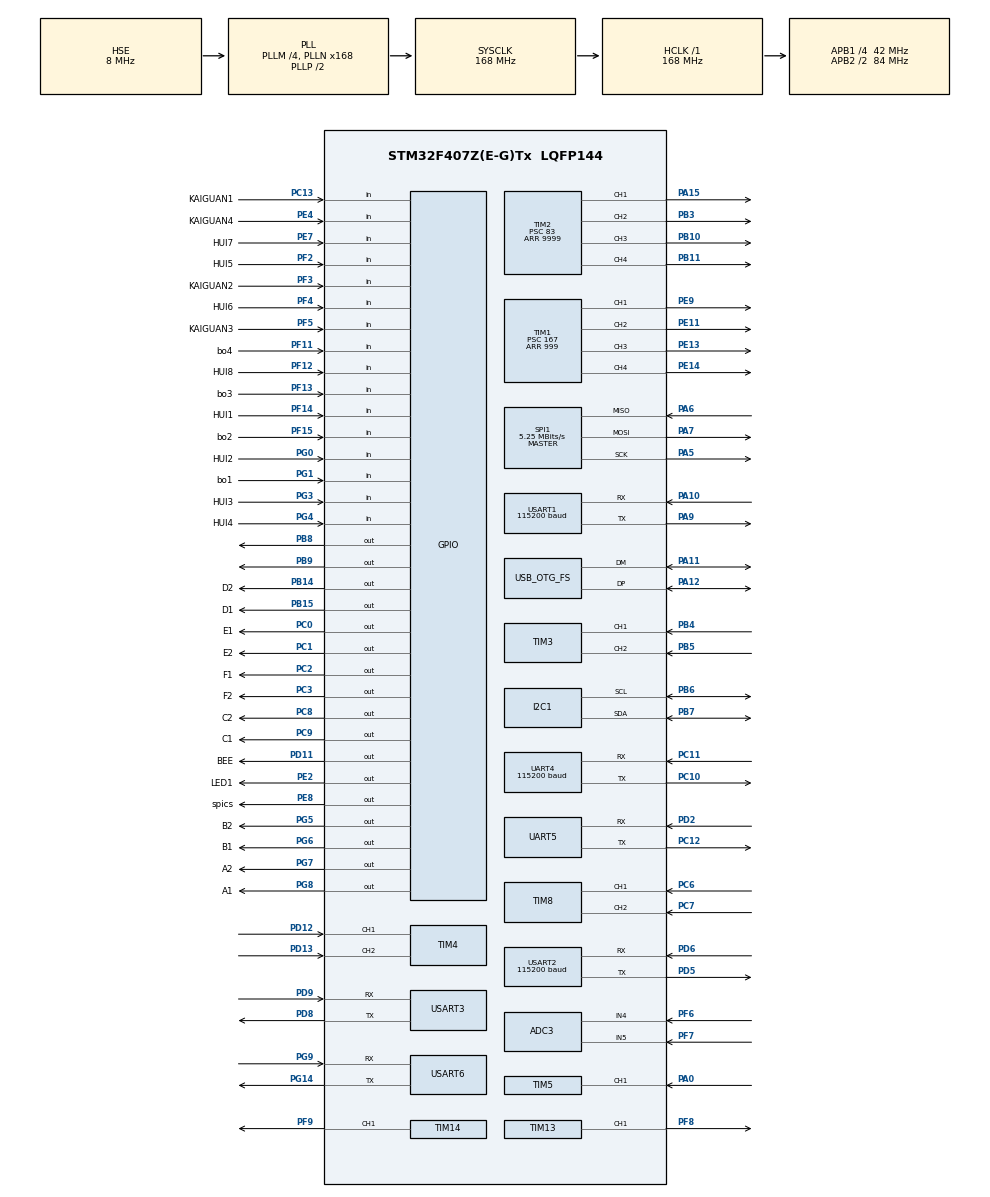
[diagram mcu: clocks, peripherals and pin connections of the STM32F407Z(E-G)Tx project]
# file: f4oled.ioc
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ADC3.Channel-0\#ChannelRegularConversion=ADC_CHANNEL_4
ADC3.Channel-1\#ChannelRegularConversion=ADC_CHANNEL_5
ADC3.ContinuousConvMode=ENABLE
ADC3.DMAContinuousRequests=ENABLE
ADC3.EOCSelection=ADC_EOC_SEQ_CONV
ADC3.NbrOfConversion=2
ADC3.NbrOfConversionFlag=1
ADC3.Rank-0\#ChannelRegularConversion=1
ADC3.Rank-1\#ChannelRegularConversion=2
ADC3.SamplingTime-0\#ChannelRegularConversion=ADC_SAMPLETIME_15CYCLES
ADC3.SamplingTime-1\#ChannelRegularConversion=ADC_SAMPLETIME_15CYCLES
ADC3.ScanConvMode=ENABLE
Dma.ADC3.8.Direction=DMA_PERIPH_TO_MEMORY
Dma.ADC3.8.FIFOMode=DMA_FIFOMODE_DISABLE
Dma.ADC3.8.Instance=DMA2_Stream0
Dma.ADC3.8.MemDataAlignment=DMA_MDATAALIGN_HALFWORD
Dma.ADC3.8.MemInc=DMA_MINC_ENABLE
Dma.ADC3.8.Mode=DMA_CIRCULAR
Dma.ADC3.8.PeriphDataAlignment=DMA_PDATAALIGN_HALFWORD
Dma.ADC3.8.PeriphInc=DMA_PINC_DISABLE
Dma.ADC3.8.Priority=DMA_PRIORITY_LOW
Dma.Request0=USART1_RX
Dma.Request1=USART1_TX
Dma.Request10=USART3_TX
Dma.Request2=UART5_RX
Dma.Request3=UART5_TX
Dma.Request4=UART4_RX
Dma.Request5=UART4_TX
Dma.Request6=USART2_RX
Dma.Request7=USART2_TX
Dma.Request8=ADC3
Dma.Request9=USART3_RX
Dma.UART4_RX.4.Direction=DMA_PERIPH_TO_MEMORY
Dma.UART4_RX.4.FIFOMode=DMA_FIFOMODE_DISABLE
Dma.UART4_RX.4.Instance=DMA1_Stream2
Dma.UART4_RX.4.MemDataAlignment=DMA_MDATAALIGN_BYTE
Dma.UART4_RX.4.MemInc=DMA_MINC_ENABLE
Dma.UART4_RX.4.Mode=DMA_NORMAL
Dma.UART4_RX.4.PeriphDataAlignment=DMA_PDATAALIGN_BYTE
Dma.UART4_RX.4.PeriphInc=DMA_PINC_DISABLE
Dma.UART4_RX.4.Priority=DMA_PRIORITY_LOW
Dma.UART4_TX.5.Direction=DMA_MEMORY_TO_PERIPH
Dma.UART4_TX.5.FIFOMode=DMA_FIFOMODE_DISABLE
Dma.UART4_TX.5.Instance=DMA1_Stream4
Dma.UART4_TX.5.MemDataAlignment=DMA_MDATAALIGN_BYTE
Dma.UART4_TX.5.MemInc=DMA_MINC_ENABLE
Dma.UART4_TX.5.Mode=DMA_NORMAL
Dma.UART4_TX.5.PeriphDataAlignment=DMA_PDATAALIGN_BYTE
Dma.UART4_TX.5.PeriphInc=DMA_PINC_DISABLE
Dma.UART4_TX.5.Priority=DMA_PRIORITY_LOW
Dma.UART5_RX.2.Direction=DMA_PERIPH_TO_MEMORY
Dma.UART5_RX.2.FIFOMode=DMA_FIFOMODE_DISABLE
Dma.UART5_RX.2.Instance=DMA1_Stream0
Dma.UART5_RX.2.MemDataAlignment=DMA_MDATAALIGN_BYTE
Dma.UART5_RX.2.MemInc=DMA_MINC_ENABLE
Dma.UART5_RX.2.Mode=DMA_NORMAL
Dma.UART5_RX.2.PeriphDataAlignment=DMA_PDATAALIGN_BYTE
Dma.UART5_RX.2.PeriphInc=DMA_PINC_DISABLE
Dma.UART5_RX.2.Priority=DMA_PRIORITY_LOW
Dma.UART5_TX.3.Direction=DMA_MEMORY_TO_PERIPH
Dma.UART5_TX.3.FIFOMode=DMA_FIFOMODE_DISABLE
Dma.UART5_TX.3.Instance=DMA1_Stream7
Dma.UART5_TX.3.MemDataAlignment=DMA_MDATAALIGN_BYTE
Dma.UART5_TX.3.MemInc=DMA_MINC_ENABLE
Dma.UART5_TX.3.Mode=DMA_NORMAL
Dma.UART5_TX.3.PeriphDataAlignment=DMA_PDATAALIGN_BYTE
Dma.UART5_TX.3.PeriphInc=DMA_PINC_DISABLE
Dma.UART5_TX.3.Priority=DMA_PRIORITY_LOW
Dma.USART1_RX.0.Direction=DMA_PERIPH_TO_MEMORY
Dma.USART1_RX.0.FIFOMode=DMA_FIFOMODE_DISABLE
Dma.USART1_RX.0.Instance=DMA2_Stream2
Dma.USART1_RX.0.MemDataAlignment=DMA_MDATAALIGN_BYTE
Dma.USART1_RX.0.MemInc=DMA_MINC_ENABLE
Dma.USART1_RX.0.Mode=DMA_NORMAL
Dma.USART1_RX.0.PeriphDataAlignment=DMA_PDATAALIGN_BYTE
Dma.USART1_RX.0.PeriphInc=DMA_PINC_DISABLE
Dma.USART1_RX.0.Priority=DMA_PRIORITY_LOW
Dma.USART1_TX.1.Direction=DMA_MEMORY_TO_PERIPH
Dma.USART1_TX.1.FIFOMode=DMA_FIFOMODE_DISABLE
Dma.USART1_TX.1.Instance=DMA2_Stream7
Dma.USART1_TX.1.MemDataAlignment=DMA_MDATAALIGN_BYTE
Dma.USART1_TX.1.MemInc=DMA_MINC_ENABLE
Dma.USART1_TX.1.Mode=DMA_NORMAL
Dma.USART1_TX.1.PeriphDataAlignment=DMA_PDATAALIGN_BYTE
Dma.USART1_TX.1.PeriphInc=DMA_PINC_DISABLE
Dma.USART1_TX.1.Priority=DMA_PRIORITY_LOW
Dma.USART2_RX.6.Direction=DMA_PERIPH_TO_MEMORY
Dma.USART2_RX.6.FIFOMode=DMA_FIFOMODE_DISABLE
Dma.USART2_RX.6.Instance=DMA1_Stream5
Dma.USART2_RX.6.MemDataAlignment=DMA_MDATAALIGN_BYTE
Dma.USART2_RX.6.MemInc=DMA_MINC_ENABLE
Dma.USART2_RX.6.Mode=DMA_NORMAL
Dma.USART2_RX.6.PeriphDataAlignment=DMA_PDATAALIGN_BYTE
Dma.USART2_RX.6.PeriphInc=DMA_PINC_DISABLE
Dma.USART2_RX.6.Priority=DMA_PRIORITY_LOW
Dma.USART2_TX.7.Direction=DMA_MEMORY_TO_PERIPH
Dma.USART2_TX.7.FIFOMode=DMA_FIFOMODE_DISABLE
Dma.USART2_TX.7.Instance=DMA1_Stream6
Dma.USART2_TX.7.MemDataAlignment=DMA_MDATAALIGN_BYTE
Dma.USART2_TX.7.MemInc=DMA_MINC_ENABLE
Dma.USART2_TX.7.Mode=DMA_NORMAL
Dma.USART2_TX.7.PeriphDataAlignment=DMA_PDATAALIGN_BYTE
Dma.USART2_TX.7.PeriphInc=DMA_PINC_DISABLE
Dma.USART2_TX.7.Priority=DMA_PRIORITY_LOW
Dma.USART3_RX.9.Direction=DMA_PERIPH_TO_MEMORY
Dma.USART3_RX.9.FIFOMode=DMA_FIFOMODE_DISABLE
Dma.USART3_RX.9.Instance=DMA1_Stream1
Dma.USART3_RX.9.MemDataAlignment=DMA_MDATAALIGN_BYTE
Dma.USART3_RX.9.MemInc=DMA_MINC_ENABLE
Dma.USART3_RX.9.Mode=DMA_NORMAL
Dma.USART3_RX.9.PeriphDataAlignment=DMA_PDATAALIGN_BYTE
Dma.USART3_RX.9.PeriphInc=DMA_PINC_DISABLE
Dma.USART3_RX.9.Priority=DMA_PRIORITY_LOW
Dma.USART3_TX.10.Direction=DMA_MEMORY_TO_PERIPH
Dma.USART3_TX.10.FIFOMode=DMA_FIFOMODE_DISABLE
Dma.USART3_TX.10.Instance=DMA1_Stream3
Dma.USART3_TX.10.MemDataAlignment=DMA_MDATAALIGN_BYTE
Dma.USART3_TX.10.MemInc=DMA_MINC_ENABLE
Dma.USART3_TX.10.Mode=DMA_NORMAL
Dma.USART3_TX.10.PeriphDataAlignment=DMA_PDATAALIGN_BYTE
Dma.USART3_TX.10.PeriphInc=DMA_PINC_DISABLE
Dma.USART3_TX.10.Priority=DMA_PRIORITY_LOW
Mcu.Family=STM32F4
Mcu.Name=STM32F407Z(E-G)Tx
Mcu.Package=LQFP144
NVIC.DMA1_Stream0_IRQn=true\:0\:0\:false\:false\:true\:false\:true\:true
NVIC.DMA1_Stream1_IRQn=true\:0\:0\:false\:false\:true\:false\:true\:true
NVIC.DMA1_Stream2_IRQn=true\:0\:0\:false\:false\:true\:false\:true\:true
NVIC.DMA1_Stream3_IRQn=true\:0\:0\:false\:false\:true\:false\:true\:true
NVIC.DMA1_Stream4_IRQn=true\:0\:0\:false\:false\:true\:false\:true\:true
NVIC.DMA1_Stream5_IRQn=true\:0\:0\:false\:false\:true\:false\:true\:true
NVIC.DMA1_Stream6_IRQn=true\:0\:0\:false\:false\:true\:false\:true\:true
NVIC.DMA1_Stream7_IRQn=true\:0\:0\:false\:false\:true\:false\:true\:true
NVIC.DMA2_Stream0_IRQn=true\:0\:0\:false\:false\:true\:false\:true\:true
NVIC.DMA2_Stream2_IRQn=true\:0\:0\:false\:false\:true\:false\:true\:true
NVIC.DMA2_Stream7_IRQn=true\:0\:0\:false\:false\:true\:false\:true\:true
NVIC.OTG_FS_IRQn=true\:5\:0\:false\:false\:true\:false\:true\:true
NVIC.PriorityGroup=NVIC_PRIORITYGROUP_4
NVIC.TIM1_BRK_TIM9_IRQn=true\:0\:0\:false\:false\:true\:true\:true\:true
NVIC.TIM2_IRQn=true\:0\:0\:false\:false\:true\:true\:true\:true
NVIC.TIM5_IRQn=true\:0\:0\:false\:false\:true\:true\:true\:true
NVIC.TIM8_UP_TIM13_IRQn=true\:0\:0\:false\:false\:true\:true\:true\:true
NVIC.UART4_IRQn=true\:0\:0\:false\:false\:true\:true\:true\:true
NVIC.UART5_IRQn=true\:0\:0\:false\:false\:true\:true\:true\:true
NVIC.USART1_IRQn=true\:0\:0\:false\:false\:true\:true\:true\:true
NVIC.USART2_IRQn=true\:0\:0\:false\:false\:true\:true\:true\:true
NVIC.USART3_IRQn=true\:0\:0\:false\:false\:true\:true\:true\:true
PA0-WKUP.Signal=S_TIM5_CH1
PA10.Mode=Asynchronous
PA10.Signal=USART1_RX
PA11.Mode=Device_Only
PA11.Signal=USB_OTG_FS_DM
PA12.Mode=Device_Only
PA12.Signal=USB_OTG_FS_DP
PA13.Mode=Serial_Wire
PA13.Signal=SYS_JTMS-SWDIO
PA14.Mode=Serial_Wire
PA14.Signal=SYS_JTCK-SWCLK
PA15.Signal=S_TIM2_CH1_ETR
PA5.Mode=Full_Duplex_Master
PA5.Signal=SPI1_SCK
PA6.Mode=Full_Duplex_Master
PA6.Signal=SPI1_MISO
PA7.Mode=Full_Duplex_Master
PA7.Signal=SPI1_MOSI
PA9.Mode=Asynchronous
PA9.Signal=USART1_TX
PB10.Signal=S_TIM2_CH3
PB11.Signal=S_TIM2_CH4
PB14.GPIO_Label=D2
PB14.Signal=GPIO_Output
PB15.GPIO_Label=D1
PB15.Signal=GPIO_Output
PB3.Signal=S_TIM2_CH2
PB4.Signal=S_TIM3_CH1
PB5.Signal=S_TIM3_CH2
PB6.Mode=I2C
PB6.Signal=I2C1_SCL
PB7.Mode=I2C
PB7.Signal=I2C1_SDA
PB8.GPIO_ModeDefaultOutputPP=GPIO_MODE_OUTPUT_OD
PB8.GPIO_PuPd=GPIO_NOPULL
PB8.Signal=GPIO_Output
PB9.GPIO_ModeDefaultOutputPP=GPIO_MODE_OUTPUT_OD
PB9.GPIO_PuPd=GPIO_NOPULL
PB9.Signal=GPIO_Output
PC0.GPIO_Label=E1
PC0.Signal=GPIO_Output
PC1.GPIO_Label=E2
PC1.Signal=GPIO_Output
PC10.Mode=Asynchronous
PC10.Signal=UART4_TX
PC11.Mode=Asynchronous
PC11.Signal=UART4_RX
PC12.Mode=Asynchronous
PC12.Signal=UART5_TX
PC13-ANTI_TAMP.GPIO_Label=KAIGUAN1
PC13-ANTI_TAMP.GPIO_PuPd=GPIO_PULLUP
PC13-ANTI_TAMP.Signal=GPIO_Input
PC2.GPIO_Label=F1
PC2.Signal=GPIO_Output
PC3.GPIO_Label=F2
PC3.Signal=GPIO_Output
PC6.Signal=S_TIM8_CH1
PC7.Signal=S_TIM8_CH2
PC8.GPIO_Label=C2
PC8.Signal=GPIO_Output
PC9.GPIO_Label=C1
PC9.Signal=GPIO_Output
PD11.GPIO_Label=BEE
PD11.Signal=GPIO_Output
PD12.Signal=S_TIM4_CH1
PD13.Signal=S_TIM4_CH2
PD2.Mode=Asynchronous
PD2.Signal=UART5_RX
PD5.Mode=Asynchronous
PD5.Signal=USART2_TX
PD6.Mode=Asynchronous
PD6.Signal=USART2_RX
PD8.Mode=Asynchronous
PD8.Signal=USART3_TX
PD9.Mode=Asynchronous
PD9.Signal=USART3_RX
PE11.Signal=S_TIM1_CH2
PE13.Signal=S_TIM1_CH3
PE14.Signal=S_TIM1_CH4
PE2.GPIO_Label=LED1
PE2.Signal=GPIO_Output
PE4.GPIO_Label=KAIGUAN4
PE4.GPIO_PuPd=GPIO_PULLUP
PE4.Signal=GPIO_Input
PE7.GPIO_Label=HUI7
PE7.Signal=GPIO_Input
PE8.GPIO_Label=spics
PE8.PinState=GPIO_PIN_SET
PE8.Signal=GPIO_Output
PE9.Signal=S_TIM1_CH1
PF11.GPIO_Label=bo4
PF11.GPIO_PuPd=GPIO_PULLDOWN
PF11.Signal=GPIO_Input
PF12.GPIO_Label=HUI8
PF12.Signal=GPIO_Input
PF13.GPIO_Label=bo3
PF13.GPIO_PuPd=GPIO_PULLDOWN
PF13.Signal=GPIO_Input
PF14.GPIO_Label=HUI1
PF14.Signal=GPIO_Input
PF15.GPIO_Label=bo2
PF15.GPIO_PuPd=GPIO_PULLDOWN
PF15.Signal=GPIO_Input
PF2.GPIO_Label=HUI5
PF2.Signal=GPIO_Input
PF3.GPIO_Label=KAIGUAN2
PF3.GPIO_PuPd=GPIO_PULLUP
PF3.Signal=GPIO_Input
PF4.GPIO_Label=HUI6
PF4.Signal=GPIO_Input
PF5.GPIO_Label=KAIGUAN3
PF5.GPIO_PuPd=GPIO_PULLUP
PF5.Signal=GPIO_Input
PF6.Mode=IN4
PF6.Signal=ADC3_IN4
PF7.Mode=IN5
PF7.Signal=ADC3_IN5
PF8.Signal=S_TIM13_CH1
PF9.Signal=S_TIM14_CH1
PG0.GPIO_Label=HUI2
PG0.Signal=GPIO_Input
PG1.GPIO_Label=bo1
PG1.GPIO_PuPd=GPIO_PULLDOWN
PG1.Signal=GPIO_Input
PG14.Mode=Asynchronous
PG14.Signal=USART6_TX
PG3.GPIO_Label=HUI3
PG3.Signal=GPIO_Input
PG4.GPIO_Label=HUI4
PG4.Signal=GPIO_Input
PG5.GPIO_Label=B2
PG5.Signal=GPIO_Output
PG6.GPIO_Label=B1
PG6.Signal=GPIO_Output
PG7.GPIO_Label=A2
PG7.Signal=GPIO_Output
PG8.GPIO_Label=A1
PG8.Signal=GPIO_Output
PG9.Mode=Asynchronous
PG9.Signal=USART6_RX
PH0-OSC_IN.Mode=HSE-External-Oscillator
PH0-OSC_IN.Signal=RCC_OSC_IN
PH1-OSC_OUT.Mode=HSE-External-Oscillator
PH1-OSC_OUT.Signal=RCC_OSC_OUT
ProjectManager.HeapSize=0x200
ProjectManager.StackSize=0x400
ProjectManager.TargetToolchain=CMake
RCC.48MHZClocksFreq_Value=48000000
RCC.AHBFreq_Value=168000000
RCC.APB1CLKDivider=RCC_HCLK_DIV4
RCC.APB1Freq_Value=42000000
RCC.APB1TimFreq_Value=84000000
RCC.APB2CLKDivider=RCC_HCLK_DIV2
RCC.APB2Freq_Value=84000000
RCC.APB2TimFreq_Value=168000000
RCC.CortexFreq_Value=168000000
RCC.HCLKFreq_Value=168000000
RCC.HSE_VALUE=8000000
RCC.HSI_VALUE=16000000
RCC.LSE_VALUE=32768
RCC.PLLM=4
RCC.PLLN=168
RCC.PLLQ=7
RCC.SYSCLKFreq_VALUE=168000000
RCC.SYSCLKSource=RCC_SYSCLKSOURCE_PLLCLK
RCC.VCOOutputFreq_Value=336000000
SH.S_TIM13_CH1.0=TIM13_CH1,PWM Generation1 CH1
SH.S_TIM14_CH1.0=TIM14_CH1,PWM Generation1 CH1
SH.S_TIM1_CH1.0=TIM1_CH1,PWM Generation1 CH1
SH.S_TIM1_CH2.0=TIM1_CH2,PWM Generation2 CH2
SH.S_TIM1_CH3.0=TIM1_CH3,PWM Generation3 CH3
SH.S_TIM1_CH4.0=TIM1_CH4,PWM Generation4 CH4
SH.S_TIM2_CH1_ETR.0=TIM2_CH1,PWM Generation1 CH1
SH.S_TIM2_CH2.0=TIM2_CH2,PWM Generation2 CH2
SH.S_TIM2_CH3.0=TIM2_CH3,PWM Generation3 CH3
SH.S_TIM2_CH4.0=TIM2_CH4,PWM Generation4 CH4
SH.S_TIM3_CH1.0=TIM3_CH1,Encoder_Interface
SH.S_TIM3_CH2.0=TIM3_CH2,Encoder_Interface
SH.S_TIM4_CH1.0=TIM4_CH1,Encoder_Interface
SH.S_TIM4_CH2.0=TIM4_CH2,Encoder_Interface
SH.S_TIM5_CH1.0=TIM5_CH1,Input_Capture1_from_TI1
SH.S_TIM8_CH1.0=TIM8_CH1,Encoder_Interface
SH.S_TIM8_CH2.0=TIM8_CH2,Encoder_Interface
SPI1.BaudRatePrescaler=SPI_BAUDRATEPRESCALER_16
SPI1.CalculateBaudRate=5.25 MBits/s
SPI1.Direction=SPI_DIRECTION_2LINES
SPI1.Mode=SPI_MODE_MASTER
SPI1.VirtualType=VM_MASTER
TIM1.Channel-PWM\ Generation1\ CH1=TIM_CHANNEL_1
TIM1.Channel-PWM\ Generation2\ CH2=TIM_CHANNEL_2
TIM1.Channel-PWM\ Generation3\ CH3=TIM_CHANNEL_3
TIM1.Channel-PWM\ Generation4\ CH4=TIM_CHANNEL_4
TIM1.Period=999
TIM1.Prescaler=167
TIM13.Channel=TIM_CHANNEL_1
TIM14.Channel=TIM_CHANNEL_1
TIM2.Channel-PWM\ Generation1\ CH1=TIM_CHANNEL_1
TIM2.Channel-PWM\ Generation2\ CH2=TIM_CHANNEL_2
TIM2.Channel-PWM\ Generation3\ CH3=TIM_CHANNEL_3
TIM2.Channel-PWM\ Generation4\ CH4=TIM_CHANNEL_4
TIM2.Period=9999
TIM2.Prescaler=83
TIM3.EncoderMode=TIM_ENCODERMODE_TI12
TIM3.IC2Polarity=TIM_ICPOLARITY_FALLING
TIM4.EncoderMode=TIM_ENCODERMODE_TI12
TIM4.IC2Polarity=TIM_ICPOLARITY_FALLING
TIM5.Channel-Input_Capture1_from_TI1=TIM_CHANNEL_1
TIM5.Prescaler=83
TIM9.Period=999
TIM9.Prescaler=167
UART4.BaudRate=115200
UART4.VirtualMode=Asynchronous
UART5.VirtualMode=Asynchronous
USART1.BaudRate=115200
USART1.VirtualMode=VM_ASYNC
USART2.BaudRate=115200
USART2.VirtualMode=VM_ASYNC
USART3.VirtualMode=VM_ASYNC
USART6.VirtualMode=VM_ASYNC
USB_DEVICE.CLASS_NAME_FS=CDC
USB_DEVICE.VirtualMode-CDC_FS=Cdc
USB_DEVICE.VirtualModeFS=Cdc_FS
USB_OTG_FS.VirtualMode=Device_Only
VP_TIM13_VS_ClockSourceINT.Mode=Enable_Timer
VP_TIM14_VS_ClockSourceINT.Mode=Enable_Timer
VP_TIM1_VS_ClockSourceINT.Mode=Internal
VP_TIM2_VS_ClockSourceINT.Mode=Internal
VP_TIM5_VS_ClockSourceINT.Mode=Internal
VP_TIM9_VS_ClockSourceINT.Mode=Internal
VP_USB_DEVICE_VS_USB_DEVICE_CDC_FS.Mode=CDC_FS
board=custom

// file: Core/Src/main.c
/* USER CODE BEGIN Header */
/**
  ******************************************************************************
  * @file           : main.c
  * @brief          : Main program body
  ******************************************************************************
  * @attention
  *
  * Copyright (c) 2025 STMicroelectronics.
  * All rights reserved.
  *
  * This software is licensed under terms that can be found in the LICENSE file
  * in the root directory of this software component.
  * If no LICENSE file comes with this software, it is provided AS-IS.
  *
  ******************************************************************************
  */
/* USER CODE END Header */
#include "main.h"
#include "adc.h"
#include "dma.h"
#include "i2c.h"
#include "spi.h"
#include "tim.h"
#include "usart.h"
/* USB CDC暂时停用：需要恢复时取消本行和MX_USB_DEVICE_Init()的注释。 */
// #include "usb_device.h"
#include "gpio.h"

/* USER CODE BEGIN Includes */
#include "adc3_uart_report.h"
#include "jy61p.h"
#include "atk_ms53l0m.h"
#include "moter.h"
#include "btn.h"  /* TIM1 switches between moter and BTN in app_config.h. */
#include "encoder.h"
#include "shijue.h"
#include "doji.h"
#include "Emm_V5.h"
#include "gray.h"
#include "TJC_SCREEN.h"
#include "app_config.h"
#include "bsp_btn.h"
#include "bsp_motor.h"
#include "bsp_servo.h"
#include "bsp_time.h"
#include "bsp_uart.h"
#include "ball_control.h"
#include "state.h"
/* USER CODE END Includes */

/* USER CODE BEGIN PD */
#define PACKET_TIMEOUT 100
/* USER CODE END PD */

/* USER CODE BEGIN PV */

uint16_t count;
uint8_t count1;
uint8_t count2;
uint8_t rxBuffer1[256]= {0};
uint8_t rxBuffer4[256];
uint8_t rxBuffer5[256];
uint8_t rxBuffer2[256];
uint8_t rxBuffer3[256];
volatile uint16_t g_rx2_size = 0U;
volatile uint32_t g_jy61_rx_event_count = 0U;
volatile uint32_t g_jy61_rx_byte_count = 0U;
volatile uint32_t g_vision_rx_event_count = 0U;
volatile uint32_t g_vision_rx_byte_count = 0U;
volatile uint32_t g_vision_rx_restart_fail_count = 0U;
volatile uint32_t g_vision_uart_error_count = 0U;
volatile uint32_t g_vision_uart_last_error = 0U;
volatile uint32_t g_debug_rx_restart_fail_count = 0U;
volatile uint32_t g_debug_uart_error_count = 0U;
volatile uint32_t g_debug_uart_last_error = 0U;
uint8_t shijue[10];
char displayBuffer[20];
uint16_t atk_id = 0;
uint16_t atk_distance = 0;
uint8_t atk_ready = 0;
uint8_t atk_last_err = ATK_MS53L0M_ERROR;
volatile uint8_t g_roll_flag_vel = 0;
volatile uint8_t g_roll_flag_pos = 0;
/* USER CODE END PV */

void SystemClock_Config(void);

/* USER CODE BEGIN 0 */
static void Main_AppInit(void)
{
    /* 启动周期定时器和各串口的空闲中断 DMA 接收。 */
    BSP_TimeStartPeriodic();
    (void)BSP_UartStartReceiveToIdleDma(BSP_UART_1, rxBuffer1, sizeof(rxBuffer1));
    if (BSP_UartStartReceiveToIdleDma(BSP_UART_2,
                                      rxBuffer2,
                                      sizeof(rxBuffer2)) != BSP_STATUS_OK)
    {
        g_debug_rx_restart_fail_count++;
    }
    (void)BSP_UartStartReceiveToIdleDma(BSP_UART_3, rxBuffer3, sizeof(rxBuffer3));
    (void)BSP_UartStartReceiveToIdleDma(BSP_UART_4, rxBuffer4, sizeof(rxBuffer4));
    (void)BSP_UartStartReceiveToIdleDma(BSP_UART_5, rxBuffer5, sizeof(rxBuffer5));

    /* 初始化当前固件配置需要使用的设备。 */
    BSP_ServoInit();
    BallControl_Init();
    Encoder3_Init();
    Encoder4_Init();

    /* 默认不启用激光测距，避免占用当前调试输出。 */
    atk_ready = 0U;
    atk_last_err = ATK_MS53L0M_ERROR;

#if APP_UART4_MODE == APP_UART4_MODE_JY61P
    /* Recover the required packet types first, then switch to 100 Hz. */
    JY61P_Unlock();
    BSP_DelayMs(200U);
    JY61P_WriteRegister(0x02U, 0x000EU);
    BSP_DelayMs(200U);
    JY61P_WriteRegister(0x03U, 0x09);
    BSP_DelayMs(200U);
    JY61P_Save();
    BSP_DelayMs(200U);
#endif

#if APP_TIM1_MODE == APP_TIM1_MODE_MOTER
    Moter_Init();
#elif APP_TIM1_MODE == APP_TIM1_MODE_BTN
    BTN_Init();
#endif

#if APP_REPORT_ADC
    Adc3UartReport_Init();
    (void)Adc3UartReport_Start();
#endif

    /* 设置电机和舵机的上电初始输出。 */
#if APP_TIM1_MODE == APP_TIM1_MODE_MOTER
    /* 上电时保持四路电机停止。 */
    Moter_A(0);
    Moter_B(0);
    Moter_C(0);
    Moter_D(0);
#endif
    /* OLED、按键和题目逻辑统一由 state 模块管理。 */
    State_Init();
    /* PA15 舵机由 BallControl 管理，默认保持 1750 us 机械中位。 */
}

void HAL_UARTEx_RxEventCallback(UART_HandleTypeDef *huart, uint16_t Size)
{
    if (BSP_UartMatches(BSP_UART_4, huart))
    {
#if APP_UART4_MODE == APP_UART4_MODE_JY61P
      uint16_t i;
      g_jy61_rx_event_count++;
      g_jy61_rx_byte_count += Size;
      for (i = 0U; i < Size; i++)
      {
        ProcessReceivedData(rxBuffer4[i]);
      }
#elif APP_UART4_MODE == APP_UART4_MODE_ENCODER
      /* UART4 当前只发送编码器速度，收到的数据暂不解析也不回发。 */
      (void)Size;
#endif
      (void)BSP_UartStartReceiveToIdleDma(BSP_UART_4,
                                          rxBuffer4,
                                          sizeof(rxBuffer4));
    }
    else if (BSP_UartMatches(BSP_UART_1, huart))
    {
      g_vision_rx_event_count++;
      g_vision_rx_byte_count += Size;
      Shijue_ProcessRxBuffer(rxBuffer1, Size);
      if (BSP_UartStartReceiveToIdleDma(BSP_UART_1,
                                        rxBuffer1,
                                        sizeof(rxBuffer1)) != BSP_STATUS_OK)
      {
        g_vision_rx_restart_fail_count++;
      }
    }
    else if (BSP_UartMatches(BSP_UART_2, huart))
    {
        g_rx2_size = Size;
#if APP_USART2_MODE == APP_USART2_MODE_ATK_TOF
        atk_ms53l0m_uart_rx_event(rxBuffer2, Size);
#else
        State_DebugRx(rxBuffer2, Size);
#endif
        if (BSP_UartStartReceiveToIdleDma(BSP_UART_2,
                                          rxBuffer2,
                                          sizeof(rxBuffer2)) != BSP_STATUS_OK)
        {
            g_debug_rx_restart_fail_count++;
        }
    }
    else if (BSP_UartMatches(BSP_UART_3, huart))
    {
        TJC_OnRx(rxBuffer3, Size);
        (void)BSP_UartStartReceiveToIdleDma(BSP_UART_3,
                                            rxBuffer3,
                                            sizeof(rxBuffer3));
    }
    else if (BSP_UartMatches(BSP_UART_5, huart))
    {
        (void)Size;
        (void)BSP_UartStartReceiveToIdleDma(BSP_UART_5,
                                            rxBuffer5,
                                            sizeof(rxBuffer5));
    }
}

void HAL_UART_ErrorCallback(UART_HandleTypeDef *huart)
{
    if (BSP_UartMatches(BSP_UART_1, huart))
    {
        /* USART1 DMA遇到线路错误后会停止，立即重启以恢复视觉数据流。 */
        g_vision_uart_error_count++;
        g_vision_uart_last_error = huart->ErrorCode;
        if (BSP_UartStartReceiveToIdleDma(BSP_UART_1,
                                          rxBuffer1,
                                          sizeof(rxBuffer1)) != BSP_STATUS_OK)
        {
            g_vision_rx_restart_fail_count++;
        }
    }
    else if (BSP_UartMatches(BSP_UART_2, huart))
    {
        /* USART2 线路错误会终止 DMA 接收，立即重启以保留在线调参能力。 */
        g_debug_uart_error_count++;
        g_debug_uart_last_error = huart->ErrorCode;
        if (BSP_UartStartReceiveToIdleDma(BSP_UART_2,
                                          rxBuffer2,
                                          sizeof(rxBuffer2)) != BSP_STATUS_OK)
        {
            g_debug_rx_restart_fail_count++;
        }
    }
}

/* USER CODE END 0 */

int main(void)
{

  /* MCU Configuration--------------------------------------------------------*/

  /* Reset of all peripherals, Initializes the Flash interface and the Systick. */
  HAL_Init();

  /* Configure the system clock */
  SystemClock_Config();

  /* Initialize all configured peripherals */
  MX_GPIO_Init();
  MX_DMA_Init();
  MX_TIM4_Init();
  MX_TIM5_Init();
  MX_UART4_Init();
  MX_UART5_Init();
  MX_USART1_UART_Init();
  MX_USART2_UART_Init();
  MX_USART3_UART_Init();
  MX_SPI1_Init();
  MX_TIM1_Init();
  MX_TIM2_Init();
  MX_USART6_UART_Init();
  MX_TIM8_Init();
  MX_ADC3_Init();
  MX_TIM9_Init();
  MX_TIM13_Init();
  MX_TIM14_Init();
  MX_TIM3_Init();
  MX_I2C1_Init();
  /* USB CDC暂时停用，需要使用USB视觉通信时取消注释。 */
  // MX_USB_DEVICE_Init();
  /* USER CODE BEGIN 2 */
    Main_AppInit();
  /* USER CODE END 2 */

  /* Infinite loop */
  /* USER CODE BEGIN WHILE */
    /* 临时舵机调试：PA15/PB3/PB10/PB11 四路均固定为1750 us。 */

    while (1)
    {
      State_RunCurrent();

    /* USER CODE END WHILE */

    }
}

void SystemClock_Config(void)
{
  RCC_OscInitTypeDef RCC_OscInitStruct = {0};
  RCC_ClkInitTypeDef RCC_ClkInitStruct = {0};

  /** Configure the main internal regulator output voltage
  */
  __HAL_RCC_PWR_CLK_ENABLE();
  __HAL_PWR_VOLTAGESCALING_CONFIG(PWR_REGULATOR_VOLTAGE_SCALE1);

  /** Initializes the RCC Oscillators according to the specified parameters
  * in the RCC_OscInitTypeDef structure.
  */
  RCC_OscInitStruct.OscillatorType = RCC_OSCILLATORTYPE_HSE;
  RCC_OscInitStruct.HSEState = RCC_HSE_ON;
  RCC_OscInitStruct.PLL.PLLState = RCC_PLL_ON;
  RCC_OscInitStruct.PLL.PLLSource = RCC_PLLSOURCE_HSE;
  RCC_OscInitStruct.PLL.PLLM = 4;
  RCC_OscInitStruct.PLL.PLLN = 168;
  RCC_OscInitStruct.PLL.PLLP = RCC_PLLP_DIV2;
  RCC_OscInitStruct.PLL.PLLQ = 7;
  if (HAL_RCC_OscConfig(&RCC_OscInitStruct) != HAL_OK)
  {
    Error_Handler();
  }

  /** Initializes the CPU, AHB and APB buses clocks
  */
  RCC_ClkInitStruct.ClockType = RCC_CLOCKTYPE_HCLK|RCC_CLOCKTYPE_SYSCLK
                              |RCC_CLOCKTYPE_PCLK1|RCC_CLOCKTYPE_PCLK2;
  RCC_ClkInitStruct.SYSCLKSource = RCC_SYSCLKSOURCE_PLLCLK;
  RCC_ClkInitStruct.AHBCLKDivider = RCC_SYSCLK_DIV1;
  RCC_ClkInitStruct.APB1CLKDivider = RCC_HCLK_DIV4;
  RCC_ClkInitStruct.APB2CLKDivider = RCC_HCLK_DIV2;

  if (HAL_RCC_ClockConfig(&RCC_ClkInitStruct, FLASH_LATENCY_5) != HAL_OK)
  {
    Error_Handler();
  }
}

/* USER CODE BEGIN 4 */
void HAL_TIM_PeriodElapsedCallback(TIM_HandleTypeDef *htim)
{
  if (htim->Instance == TIM9)
  {
    static uint8_t encoder_tick = 0U;

    count++;
    encoder_tick++;

    if (encoder_tick >= 10U)
    {
      encoder_tick = 0U;
      Encoder3_Update10ms();
      Encoder4_Update10ms();
    }

    if (count >= 1000U)
    {
      count = 0;
      count1++;
    }
  }
}

/* USER CODE END 4 */

void Error_Handler(void)
{
  __disable_irq();
  while (1)
  {
  }
}
